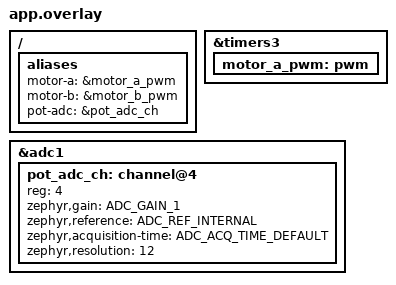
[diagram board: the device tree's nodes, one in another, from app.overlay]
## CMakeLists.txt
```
# SPDX-License-Identifier: Apache-2.0
cmake_minimum_required(VERSION 3.20.0)

find_package(Zephyr REQUIRED HINTS $ENV{ZEPHYR_BASE})
project(servodrive_zephyr C)

target_sources(app PRIVATE
  src/main.c
  src/pid.c
  src/motor.c
  src/encoder.c
  src/i2c_slave.c
)
```

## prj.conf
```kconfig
# ServoDrive (Zephyr reference) - application config.

CONFIG_LOG=y

# Peripherals
CONFIG_GPIO=y
CONFIG_PWM=y
CONFIG_ADC=y
CONFIG_I2C=y

# I2C target (slave) support
CONFIG_I2C_TARGET=y

# FPU (DCE math in float); target MCU must have an FPU (e.g. G431).
CONFIG_FPU=y

CONFIG_MAIN_STACK_SIZE=2048
CONFIG_ASSERT=y
```

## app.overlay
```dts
/*
 * Device aliases the ServoDrive firmware expects. Default values target the
 * nucleo_g431rb; adapt to the real board / a respun ServoDrive v2.
 *
 *   motor_a / motor_b : two PWM channels for the sign-magnitude H-bridge
 *   pot_adc           : ADC channel reading the feedback potentiometer
 *
 * TODO: confirm timer channels, pins and ADC channel for the target board.
 */
/ {
	aliases {
		motor-a = &motor_a_pwm;
		motor-b = &motor_b_pwm;
		pot-adc = &pot_adc_ch;
	};
};

/* Example PWM channels on TIM (adjust node/channel for the board). */
&timers3 {
	status = "okay";
	motor_a_pwm: pwm {
		status = "okay";
	};
};

/* The ADC node + channel for the potentiometer (adjust for the board). */
&adc1 {
	status = "okay";
	pot_adc_ch: channel@4 {
		reg = <4>;
		zephyr,gain = "ADC_GAIN_1";
		zephyr,reference = "ADC_REF_INTERNAL";
		zephyr,acquisition-time = <ADC_ACQ_TIME_DEFAULT>;
		zephyr,resolution = <12>;
	};
};
```

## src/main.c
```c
/*
 * ServoDrive (Zephyr reference firmware) - one joint controller.
 *
 * Reference/blueprint for an RTOS-capable ServoDrive (see ../../hardware/
 * servodrive-v2/DESIGN.md). Default target: nucleo_g431rb (the F042 cannot host
 * Zephyr). The control law matches the original DCE position controller.
 *
 * A 200 Hz control thread:
 *   read pot (ADC) -> angle -> DCE update -> drive H-bridge.
 * An I2C target accepts angle/gain commands from the head MCU.
 */
#include <zephyr/kernel.h>
#include <zephyr/logging/log.h>

#include "pid.h"
#include "motor.h"
#include "encoder.h"
#include "i2c_slave.h"

LOG_MODULE_REGISTER(eb_servo_main, LOG_LEVEL_INF);

#define CONTROL_HZ      200
#define CONTROL_PERIOD  K_MSEC(1000 / CONTROL_HZ)

/* Defaults mirror the original firmware. */
#define DEF_KP          10.0f
#define DEF_KI          0.0f
#define DEF_KV          0.0f
#define DEF_KD          50.0f
#define DEF_INT_LIMIT   500.0f
#define DEF_OUT_LIMIT   500.0f   /* maps to torque/duty headroom */
#define DEF_NODE_ID     12

struct eb_dce g_dce;             /* referenced by i2c_slave.c for gain updates */
static struct eb_servo_state g_state;

static const struct eb_pot_cal g_cal = {
	.raw_min = 250, .raw_max = 3000, .angle_min = 0.0f, .angle_max = 180.0f,
};

static void control_thread(void)
{
	float prev_angle = 0.0f;

	while (1) {
		int raw = eb_encoder_read_raw();

		if (raw >= 0) {
			float angle = eb_encoder_raw_to_angle(&g_cal, raw);
			float vel = angle - prev_angle;

			g_state.current_angle = angle;
			g_state.current_velocity = vel;
			prev_angle = angle;

			if (g_state.enabled) {
				float cmd = eb_dce_update(&g_dce,
							  g_state.target_angle,
							  angle, vel);
				eb_motor_drive(cmd);
			} else {
				eb_motor_stop();
			}
		}
		k_sleep(CONTROL_PERIOD);
	}
}

K_THREAD_DEFINE(eb_ctrl_tid, 1024, control_thread, NULL, NULL, NULL,
		K_PRIO_COOP(2), 0, 0);

int main(void)
{
	LOG_INF("servodrive-zephyr boot");

	eb_dce_init(&g_dce, DEF_KP, DEF_KI, DEF_KV, DEF_KD,
		    DEF_INT_LIMIT, DEF_OUT_LIMIT);
	g_state.node_id = DEF_NODE_ID;
	g_state.target_angle = 90.0f;
	g_state.enabled = 0;

	if (eb_motor_init() || eb_encoder_init() ||
	    eb_i2c_slave_init(&g_state)) {
		LOG_ERR("peripheral init failed");
		return -EIO;
	}

	/* control_thread runs via K_THREAD_DEFINE */
	return 0;
}
```

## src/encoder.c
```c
/*
 * Potentiometer feedback via Zephyr ADC.
 */
#include <zephyr/kernel.h>
#include <zephyr/device.h>
#include <zephyr/drivers/adc.h>
#include <zephyr/logging/log.h>

#include "encoder.h"

LOG_MODULE_REGISTER(eb_encoder, LOG_LEVEL_INF);

#define ADC_NODE DT_ALIAS(pot_adc)

static const struct adc_dt_spec adc_ch = ADC_DT_SPEC_GET(DT_ALIAS(pot_adc));
static int16_t s_sample;

int eb_encoder_init(void)
{
	if (!adc_is_ready_dt(&adc_ch)) {
		LOG_ERR("ADC not ready");
		return -ENODEV;
	}
	return adc_channel_setup_dt(&adc_ch);
}

int eb_encoder_read_raw(void)
{
	struct adc_sequence seq = {
		.buffer = &s_sample,
		.buffer_size = sizeof(s_sample),
	};

	(void)adc_sequence_init_dt(&adc_ch, &seq);
	if (adc_read_dt(&adc_ch, &seq) < 0) {
		return -EIO;
	}
	return s_sample;
}

float eb_encoder_raw_to_angle(const struct eb_pot_cal *cal, int raw)
{
	float span_raw = (float)(cal->raw_max - cal->raw_min);
	float span_ang = cal->angle_max - cal->angle_min;
	float t;

	if (span_raw == 0.0f) {
		return cal->angle_min;
	}
	t = ((float)(raw - cal->raw_min)) / span_raw;
	return cal->angle_min + t * span_ang;
}
```

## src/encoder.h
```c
/*
 * Position feedback - potentiometer read via ADC.
 *
 * The ServoDrive uses a potentiometer on an ADC channel (NOT a magnetic
 * encoder), linearly calibrated raw counts -> mechanical angle.
 */
#ifndef SERVODRIVE_ENCODER_H_
#define SERVODRIVE_ENCODER_H_

#include <stdint.h>

/* Calibration: raw ADC counts at the mechanical 0 and 180 degree ends. */
struct eb_pot_cal {
	int   raw_min;   /* e.g. 250  */
	int   raw_max;   /* e.g. 3000 */
	float angle_min; /* e.g. 0    */
	float angle_max; /* e.g. 180  */
};

int   eb_encoder_init(void);

/* Read the raw ADC value (averaged). Returns counts, or <0 on error. */
int   eb_encoder_read_raw(void);

/* Convert raw counts to angle (deg) using the calibration. */
float eb_encoder_raw_to_angle(const struct eb_pot_cal *cal, int raw);

#endif /* SERVODRIVE_ENCODER_H_ */
```

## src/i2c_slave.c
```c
/*
 * I2C target (slave) command handler.
 *
 * Uses Zephyr's I2C target API. The write handler decodes [opcode][float32]
 * and updates the shared servo state; the read handler returns the current
 * angle (float32, little-endian), echoing the original behavior.
 *
 * NOTE: not all STM32 I2C target drivers expose the full callback set; the
 * decode logic here is the portable part. The driver registration is the
 * integration point (marked TODO) depending on the chosen SoC.
 */
#include <zephyr/kernel.h>
#include <zephyr/device.h>
#include <zephyr/drivers/i2c.h>
#include <zephyr/logging/log.h>
#include <string.h>

#include "i2c_slave.h"
#include "pid.h"

LOG_MODULE_REGISTER(eb_i2c, LOG_LEVEL_INF);

extern struct eb_dce g_dce;  /* gain updates land here */

static struct eb_servo_state *s_state;
static uint8_t s_rx[5];
static int s_rx_len;

static float le_float(const uint8_t *p)
{
	uint32_t v = (uint32_t)p[0] | ((uint32_t)p[1] << 8) |
		     ((uint32_t)p[2] << 16) | ((uint32_t)p[3] << 24);
	float f;

	memcpy(&f, &v, sizeof(f));
	return f;
}

/* Apply one complete 5-byte command [opcode][float32]. Exposed for testing. */
void eb_i2c_apply_command(const uint8_t *cmd5)
{
	uint8_t op = cmd5[0];
	float arg = le_float(&cmd5[1]);

	switch (op) {
	case EB_OP_SET_ANGLE:   s_state->target_angle = arg; break;
	case EB_OP_SET_TORQUE:  g_dce.output_limit = arg; break;
	case EB_OP_SET_KP:      g_dce.kp = arg; break;
	case EB_OP_SET_KI:      g_dce.ki = arg; break;
	case EB_OP_SET_KV:      g_dce.kv = arg; break;
	case EB_OP_SET_KD:      g_dce.kd = arg; break;
	case EB_OP_SET_TLIMIT:  g_dce.output_limit = arg; break;
	case EB_OP_SET_ID:      s_state->node_id = (uint8_t)arg; break;
	case EB_OP_SET_INITPOS: s_state->target_angle = arg; break;
	case EB_OP_ENABLE:      s_state->enabled = (cmd5[1] != 0); break;
	default:
		LOG_WARN("unknown opcode 0x%02x", op);
		break;
	}
	/* TODO: persist ID/gains/limits to flash (settings subsystem) for
	 * EB_OP_SET_ID / SET_K* / SET_TLIMIT / SET_INITPOS, like the original
	 * emulated-EEPROM behavior. */
}

int eb_i2c_slave_init(struct eb_servo_state *state)
{
	s_state = state;
	s_rx_len = 0;

	/*
	 * TODO (driver integration): register an I2C target on the bus at
	 * address (state->node_id) using the SoC's I2C target driver, and route:
	 *   - write-received bytes -> accumulate into s_rx; on 5 bytes call
	 *     eb_i2c_apply_command(s_rx).
	 *   - read-requested -> return current_angle as 4 little-endian bytes.
	 *
	 * The command decode (eb_i2c_apply_command) is complete and testable.
	 */
	(void)s_rx;
	LOG_INF("i2c slave decode ready (driver registration is the TODO)");
	return 0;
}
```

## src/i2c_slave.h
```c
/*
 * I2C slave - command interface from the head MCU.
 *
 * Implements the same opcode set as the original ServoDrive (see the table in
 * the project recommendations / robot9.png). The head writes [opcode][float32]
 * to set targets/gains and reads back the current angle.
 */
#ifndef SERVODRIVE_I2C_SLAVE_H_
#define SERVODRIVE_I2C_SLAVE_H_

#include <stdint.h>

/* Opcodes. */
#define EB_OP_SET_ANGLE    0x01
#define EB_OP_SET_VEL      0x02
#define EB_OP_SET_TORQUE   0x03
#define EB_OP_GET_ANGLE    0x11
#define EB_OP_GET_VEL      0x12
#define EB_OP_SET_ID       0x21
#define EB_OP_SET_KP       0x22
#define EB_OP_SET_KI       0x23
#define EB_OP_SET_KV       0x24
#define EB_OP_SET_KD       0x25
#define EB_OP_SET_TLIMIT   0x26
#define EB_OP_SET_INITPOS  0x27
#define EB_OP_ENABLE       0xff

/* Shared command state updated by the I2C ISR and read by the control loop. */
struct eb_servo_state {
	volatile float target_angle;
	volatile float current_angle;
	volatile float current_velocity;
	volatile int   enabled;
	volatile uint8_t node_id;
};

int eb_i2c_slave_init(struct eb_servo_state *state);

#endif /* SERVODRIVE_I2C_SLAVE_H_ */
```

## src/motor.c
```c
/*
 * Sign-magnitude H-bridge motor driver (Zephyr PWM).
 */
#include <zephyr/kernel.h>
#include <zephyr/device.h>
#include <zephyr/drivers/pwm.h>
#include <zephyr/logging/log.h>

#include "motor.h"

LOG_MODULE_REGISTER(eb_motor, LOG_LEVEL_INF);

/* Two PWM channels for the H-bridge (devicetree aliases). */
static const struct pwm_dt_spec pwm_a = PWM_DT_SPEC_GET(DT_ALIAS(motor_a));
static const struct pwm_dt_spec pwm_b = PWM_DT_SPEC_GET(DT_ALIAS(motor_b));

/* ~48 kHz like the original (period in nanoseconds). */
#define PWM_PERIOD_NS 20833U

static void set_duty(const struct pwm_dt_spec *ch, uint32_t duty_0_1000)
{
	uint32_t pulse = (uint64_t)PWM_PERIOD_NS * duty_0_1000 / EB_MOTOR_DUTY_MAX;

	(void)pwm_set_dt(ch, PWM_PERIOD_NS, pulse);
}

int eb_motor_init(void)
{
	if (!pwm_is_ready_dt(&pwm_a) || !pwm_is_ready_dt(&pwm_b)) {
		LOG_ERR("PWM channels not ready");
		return -ENODEV;
	}
	eb_motor_stop();
	return 0;
}

void eb_motor_drive(float command)
{
	float mag = command < 0 ? -command : command;
	uint32_t duty = (uint32_t)(mag);

	if (duty > EB_MOTOR_DUTY_MAX) {
		duty = EB_MOTOR_DUTY_MAX;
	}

	if (command >= 0) {
		set_duty(&pwm_a, duty);
		set_duty(&pwm_b, 0);
	} else {
		set_duty(&pwm_a, 0);
		set_duty(&pwm_b, duty);
	}
}

void eb_motor_stop(void)
{
	set_duty(&pwm_a, 0);
	set_duty(&pwm_b, 0);
}
```

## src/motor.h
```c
/*
 * Brushed-DC motor driver - sign-magnitude H-bridge on two PWM channels.
 *
 * Matches the original ServoDrive: TIM CH1/CH2 drive the H-bridge; the sign of
 * the control output selects direction, the magnitude sets the duty (0..1000).
 */
#ifndef SERVODRIVE_MOTOR_H_
#define SERVODRIVE_MOTOR_H_

#define EB_MOTOR_DUTY_MAX 1000

int  eb_motor_init(void);

/* Drive the motor. `command` is the DCE output; positive = one direction,
 * negative = the other. Magnitude is mapped to PWM duty and clamped. */
void eb_motor_drive(float command);

void eb_motor_stop(void);

#endif /* SERVODRIVE_MOTOR_H_ */
```

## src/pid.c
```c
/*
 * DCE position controller implementation.
 */
#include "pid.h"

static float clampf(float v, float lim)
{
	if (v > lim) {
		return lim;
	}
	if (v < -lim) {
		return -lim;
	}
	return v;
}

void eb_dce_init(struct eb_dce *d, float kp, float ki, float kv, float kd,
		 float integral_limit, float output_limit)
{
	d->kp = kp;
	d->ki = ki;
	d->kv = kv;
	d->kd = kd;
	d->integral_limit = integral_limit;
	d->output_limit = output_limit;
	eb_dce_reset(d);
}

void eb_dce_reset(struct eb_dce *d)
{
	d->integral = 0.0f;
	d->vel_integral = 0.0f;
	d->prev_error = 0.0f;
}

float eb_dce_update(struct eb_dce *d, float target, float measured,
		    float velocity)
{
	float error = target - measured;
	float derivative = error - d->prev_error;

	d->integral = clampf(d->integral + error, d->integral_limit);
	d->vel_integral = clampf(d->vel_integral + velocity, d->integral_limit);

	float out = d->kp * error
		  + d->ki * d->integral
		  + d->kv * d->vel_integral
		  + d->kd * derivative;

	d->prev_error = error;
	return clampf(out, d->output_limit);
}
```

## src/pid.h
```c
/*
 * DCE ("Digital Control Engine") - the ServoDrive position controller.
 *
 * Same control law as the original firmware:
 *   out = kp*err + ki*integral + kv*vel_integral + kd*(err - prev_err)
 * with anti-windup clamping on the integrators and a final torque clamp.
 *
 * Kept as a pure, dependency-free struct so it can be unit-tested on the host
 * and reused by either a bare-metal or an RTOS build.
 */
#ifndef SERVODRIVE_PID_H_
#define SERVODRIVE_PID_H_

struct eb_dce {
	/* gains */
	float kp, ki, kv, kd;
	/* limits */
	float integral_limit;  /* anti-windup clamp (original default ~500) */
	float output_limit;    /* torque/output clamp */
	/* state */
	float integral;
	float vel_integral;
	float prev_error;
};

void  eb_dce_init(struct eb_dce *d, float kp, float ki, float kv, float kd,
		  float integral_limit, float output_limit);

void  eb_dce_reset(struct eb_dce *d);

/* One control step: target and measured in the same units (degrees).
 * `velocity` is the measured angular velocity (deg/tick); pass 0 if unused.
 * Returns the clamped control output (motor command, e.g. -limit..+limit).
 */
float eb_dce_update(struct eb_dce *d, float target, float measured,
		    float velocity);

#endif /* SERVODRIVE_PID_H_ */
```
